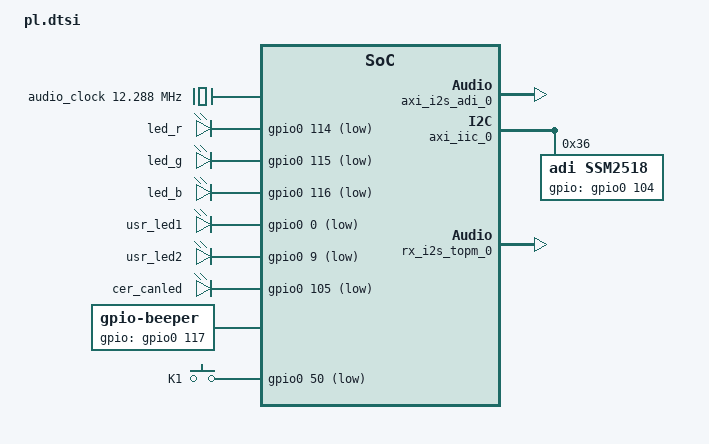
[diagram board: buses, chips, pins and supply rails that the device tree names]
/*
 * CAUTION: This file is automatically generated by Xilinx.
 * Version:  
 * Today is: Tue Feb 23 12:53:48 2016
*/


/ {
	amba_pl: amba_pl {
		#address-cells = <1>;
		#size-cells = <1>;
		compatible = "simple-bus";
		ranges ;
		auxdisp_0: auxdisp@43c20000 {
			compatible = "iit,auxdisp-1.0";
			interrupt-parent = <&intc>;
			interrupts = <0 31 4>;
			reg = <0x43c20000 0x10000>;
			xlnx,hor-module = <0x5>;
			xlnx,log2numlines = <0x4>;
			xlnx,numlines = <0x10>;
			xlnx,numrows = <0x2>;
			/* 103 = 54(offset default for gpio) + 49 */
            enable = <&gpio0 103 0>;
			/* 103 = 54(offset default for gpio) + 48 */
            vl = <&gpio0 102 0>;
		};
		axi_dma_0: dma@40400000 {
			compatible = "xlnx,axi-dma";
			interrupt-parent = <&intc>;
			interrupts = <0 29 4>;
			reg = <0x40400000 0x10000>;
			xlnx,include-sg ;
			dma-channel@40400000 {
				compatible = "xlnx,axi-dma-mm2s-channel";
				interrupts = <0 29 4>;
				xlnx,datawidth = <0x20>;
				xlnx,device-id = <0x0>;
			};
		};
		axi_i2s_adi_0: axi_i2s_adi@43c30000 {
			compatible = "adi,axi-i2s-1.00.a";
			reg = <0x43c30000 0x10000>;
			dmas = <&dmac_s 0 &dmac_s 1>;
			dma-names = "tx", "rx";
			clocks = <&clkc 15>, <&audio_clock>, <&audio_clock>;
			clock-names = "axi", "ref", "i2s";
		};
		audio_clock: audio_clock {
			compatible = "fixed-clock";
			#clock-cells = <0>;
			clock-frequency = <12288000>;
		};
		axi_iic_0: i2c@41600000 {
			#address-cells = <1>;
			#size-cells = <0>;
			compatible = "xlnx,xps-iic-2.00.a";
			interrupt-parent = <&intc>;
			interrupts = <0 36 4>;
			reg = <0x41600000 0x10000>;
		 	ssm2518: ssm2518@36 {
				compatible = "adi,ssm2518";
				reg = <0x36>;
				/* 
				 * nSD Active Low shutdown
                 * 54+50 means GPIO50,  
				 */
				gpios = <&gpio0 104 0>;
			};
		};
        cer_sound {
            compatible = "digilent,ssm2518-sound";
            audio-codec = <&ssm2518>;
            cpu-dai = <&axi_i2s_adi_0>;
        };
		gcpr_0: gcpr@43c10000 {
			compatible = "iit,gcpr-1.0";
			reg = <0x43c10000 0x10000>;
			xlnx,num-regs = <0x2>;
			xlnx,permission-regs = <0x1>;
		};
		rx_i2s_topm_0: rx_i2s_topm@43c00000 {
			compatible = "iit,micif-1.0";
			interrupt-parent = <&intc>;
			interrupts = <0 33 4>;
			reg = <0x43c00000 0x10000>;
			/* 
             * 54+55 means GPIO55,  
			 */
			mic_enable = <&gpio0 109 0>;
		};
        leds {
            compatible = "gpio-leds";

            led_r {
    		    label = "led_r";
                /*
                 * 54+(Gpio)60=114
                 */
        		gpios = <&gpio0 114 1>;
        		default-state = "on";
        		linux,default-trigger = "heartbeat";
        	};

        	led_g {
        		label = "led_g";
                /*
                 * 54+(Gpio)61=115
                 */
        		gpios = <&gpio0 115 1>;
        		default-state = "on";
        		linux,default-trigger = "heartbeat";
        	};

        	led_b {
        		label = "led_b";
                /*
                 * 54+(Gpio)62=116
                 */
        		gpios = <&gpio0 116 1>;
        		default-state = "on";
        		linux,default-trigger = "heartbeat";
        	};

        	usr_led1 {
        		label = "usr_led1";
                /*
                 * MIO0
                 */
        		gpios = <&gpio0 0 1>;
    	    	default-state = "off";
        		linux,default-trigger = "none";
        	};

        	usr_led2 {
        		label = "usr_led2";
                /*
                 * MIO9
                 */
        		gpios = <&gpio0 9 1>;
        		default-state = "off";
        		linux,default-trigger = "none";
        	};

            cer_canled {
				/*
				 * 54+(Gpio)51=105
                 */
                gpios = <&gpio0 105 1>;
                default-state = "heartbeat";
            };
		};
        gpio-beep {
	        compatible = "gpio-beeper";
	        lable = "pl-beep";
            /*
             * 54+(Gpio)63=117
             */
	        gpios = <&gpio0 117 0>;
        };

        gpio-keys {
	        compatible = "gpio-keys";
	        #address-cells = <0x1>;
	        #size-cells = <0x0>;
	        autorepeat;

	        K1 {
		        label = "K1";
				/*
				 * MIO50
                 */
		        gpios = <&gpio0 50 1>;
		        linux,code = <0x66>;
		        gpio-key,wakeup;
		        autorepeat;
	        };
        };
	};
};
